# iorx630 register map
Registers are 8-bit, access not given, no defined reset value unless marked. A register's access mark holds for its fields unless they carry their own. Addresses are absolute; registers are grouped by the start of their names; [hi:lo] are bit positions; {n}, {i} and the like mark numbered series; 'fields as' and 'values as' point back to an identical list.

## SFR (part 4 of 4)
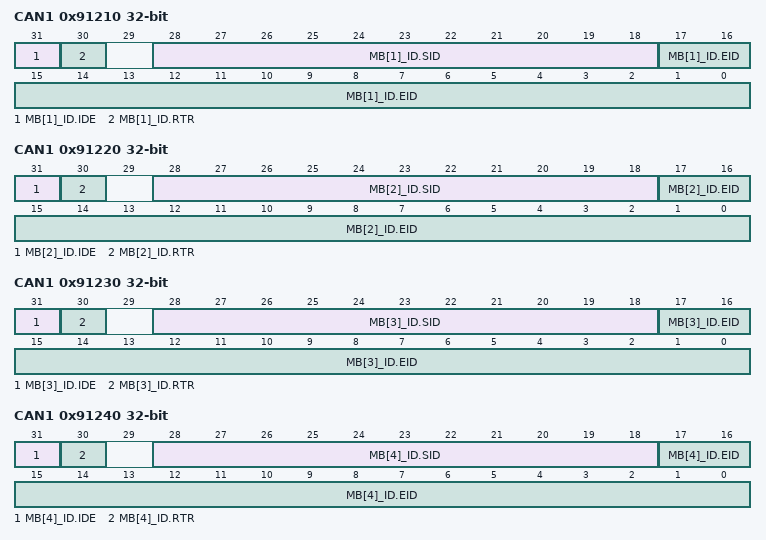
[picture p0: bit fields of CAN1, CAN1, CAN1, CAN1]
0x91210 CAN1 32-bit
  [31] MB[1]_ID.IDE, [30] MB[1]_ID.RTR, [28:18] MB[1]_ID.SID, [17:0] MB[1]_ID.EID
0x91220 CAN1 32-bit
  [31] MB[2]_ID.IDE, [30] MB[2]_ID.RTR, [28:18] MB[2]_ID.SID, [17:0] MB[2]_ID.EID
0x91230 CAN1 32-bit
  [31] MB[3]_ID.IDE, [30] MB[3]_ID.RTR, [28:18] MB[3]_ID.SID, [17:0] MB[3]_ID.EID
0x91240 CAN1 32-bit
  [31] MB[4]_ID.IDE, [30] MB[4]_ID.RTR, [28:18] MB[4]_ID.SID, [17:0] MB[4]_ID.EID
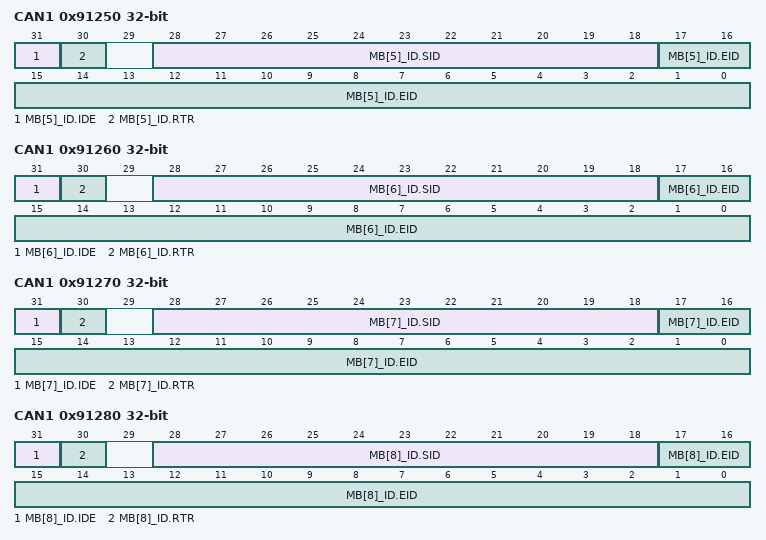
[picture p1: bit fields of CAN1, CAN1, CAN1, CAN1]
0x91250 CAN1 32-bit
  [31] MB[5]_ID.IDE, [30] MB[5]_ID.RTR, [28:18] MB[5]_ID.SID, [17:0] MB[5]_ID.EID
0x91260 CAN1 32-bit
  [31] MB[6]_ID.IDE, [30] MB[6]_ID.RTR, [28:18] MB[6]_ID.SID, [17:0] MB[6]_ID.EID
0x91270 CAN1 32-bit
  [31] MB[7]_ID.IDE, [30] MB[7]_ID.RTR, [28:18] MB[7]_ID.SID, [17:0] MB[7]_ID.EID
0x91280 CAN1 32-bit
  [31] MB[8]_ID.IDE, [30] MB[8]_ID.RTR, [28:18] MB[8]_ID.SID, [17:0] MB[8]_ID.EID
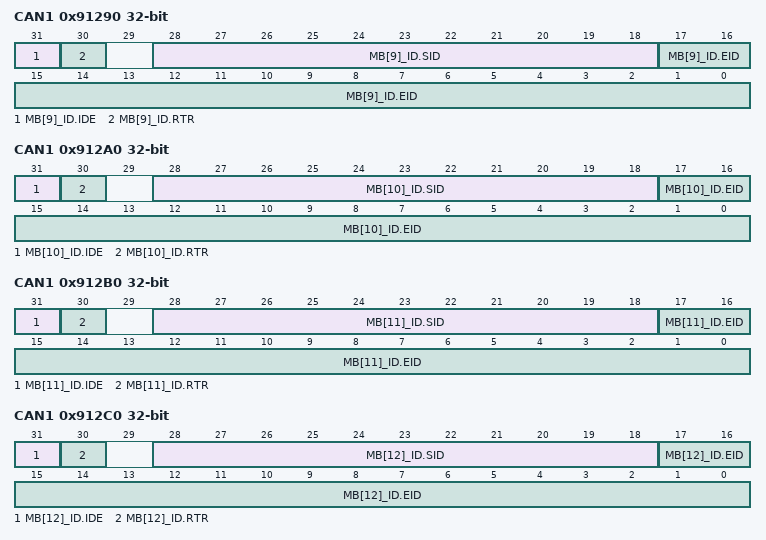
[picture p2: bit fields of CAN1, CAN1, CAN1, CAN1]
0x91290 CAN1 32-bit
  [31] MB[9]_ID.IDE, [30] MB[9]_ID.RTR, [28:18] MB[9]_ID.SID, [17:0] MB[9]_ID.EID
0x912A0 CAN1 32-bit
  [31] MB[10]_ID.IDE, [30] MB[10]_ID.RTR, [28:18] MB[10]_ID.SID, [17:0] MB[10]_ID.EID
0x912B0 CAN1 32-bit
  [31] MB[11]_ID.IDE, [30] MB[11]_ID.RTR, [28:18] MB[11]_ID.SID, [17:0] MB[11]_ID.EID
0x912C0 CAN1 32-bit
  [31] MB[12]_ID.IDE, [30] MB[12]_ID.RTR, [28:18] MB[12]_ID.SID, [17:0] MB[12]_ID.EID
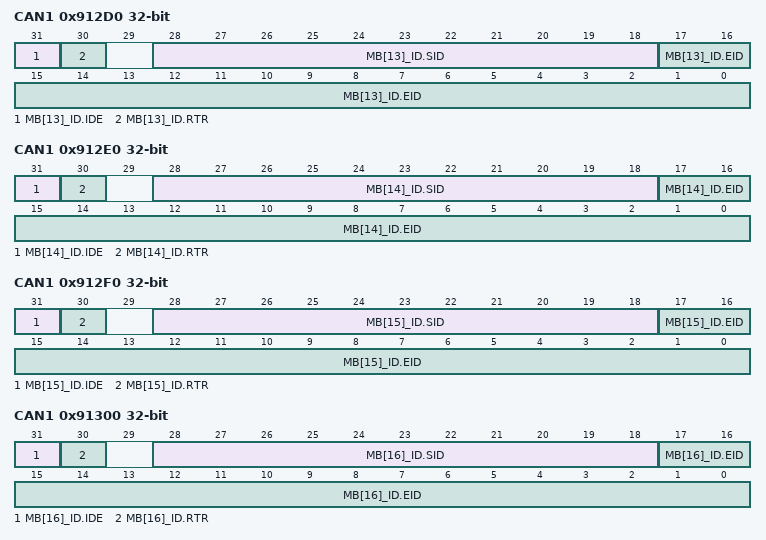
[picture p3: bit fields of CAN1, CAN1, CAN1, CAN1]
0x912D0 CAN1 32-bit
  [31] MB[13]_ID.IDE, [30] MB[13]_ID.RTR, [28:18] MB[13]_ID.SID, [17:0] MB[13]_ID.EID
0x912E0 CAN1 32-bit
  [31] MB[14]_ID.IDE, [30] MB[14]_ID.RTR, [28:18] MB[14]_ID.SID, [17:0] MB[14]_ID.EID
0x912F0 CAN1 32-bit
  [31] MB[15]_ID.IDE, [30] MB[15]_ID.RTR, [28:18] MB[15]_ID.SID, [17:0] MB[15]_ID.EID
0x91300 CAN1 32-bit
  [31] MB[16]_ID.IDE, [30] MB[16]_ID.RTR, [28:18] MB[16]_ID.SID, [17:0] MB[16]_ID.EID
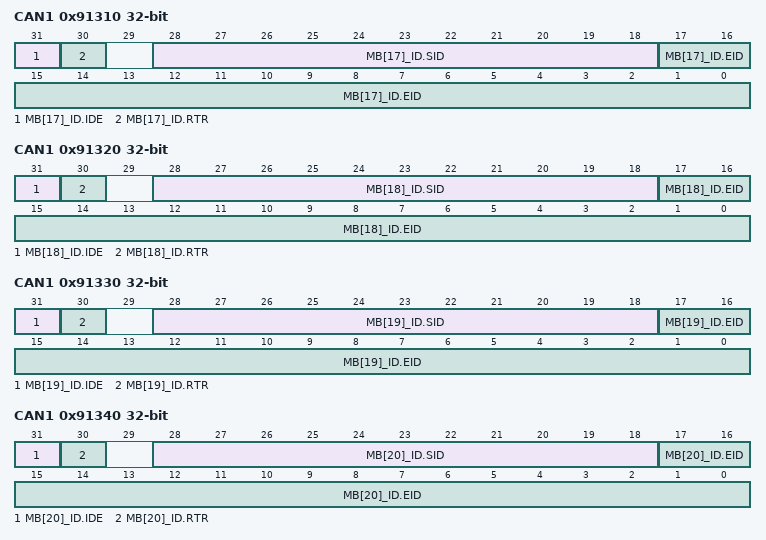
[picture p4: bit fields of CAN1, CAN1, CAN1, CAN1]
0x91310 CAN1 32-bit
  [31] MB[17]_ID.IDE, [30] MB[17]_ID.RTR, [28:18] MB[17]_ID.SID, [17:0] MB[17]_ID.EID
0x91320 CAN1 32-bit
  [31] MB[18]_ID.IDE, [30] MB[18]_ID.RTR, [28:18] MB[18]_ID.SID, [17:0] MB[18]_ID.EID
0x91330 CAN1 32-bit
  [31] MB[19]_ID.IDE, [30] MB[19]_ID.RTR, [28:18] MB[19]_ID.SID, [17:0] MB[19]_ID.EID
0x91340 CAN1 32-bit
  [31] MB[20]_ID.IDE, [30] MB[20]_ID.RTR, [28:18] MB[20]_ID.SID, [17:0] MB[20]_ID.EID
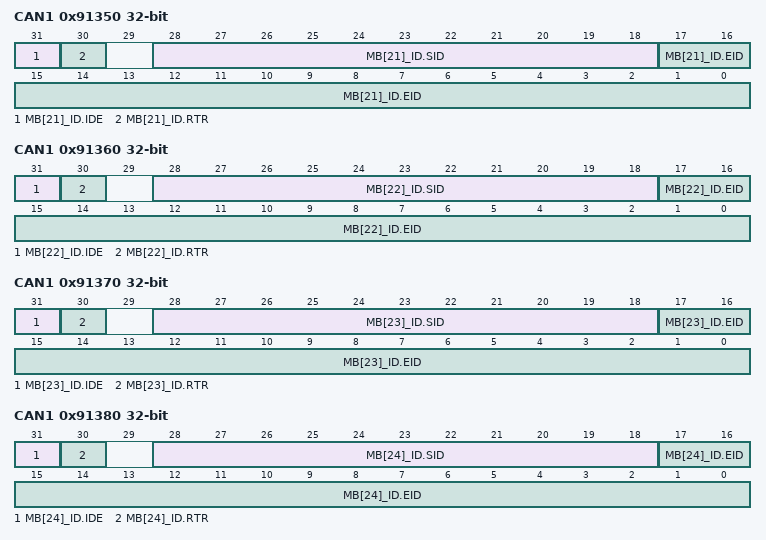
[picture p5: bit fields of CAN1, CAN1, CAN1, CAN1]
0x91350 CAN1 32-bit
  [31] MB[21]_ID.IDE, [30] MB[21]_ID.RTR, [28:18] MB[21]_ID.SID, [17:0] MB[21]_ID.EID
0x91360 CAN1 32-bit
  [31] MB[22]_ID.IDE, [30] MB[22]_ID.RTR, [28:18] MB[22]_ID.SID, [17:0] MB[22]_ID.EID
0x91370 CAN1 32-bit
  [31] MB[23]_ID.IDE, [30] MB[23]_ID.RTR, [28:18] MB[23]_ID.SID, [17:0] MB[23]_ID.EID
0x91380 CAN1 32-bit
  [31] MB[24]_ID.IDE, [30] MB[24]_ID.RTR, [28:18] MB[24]_ID.SID, [17:0] MB[24]_ID.EID
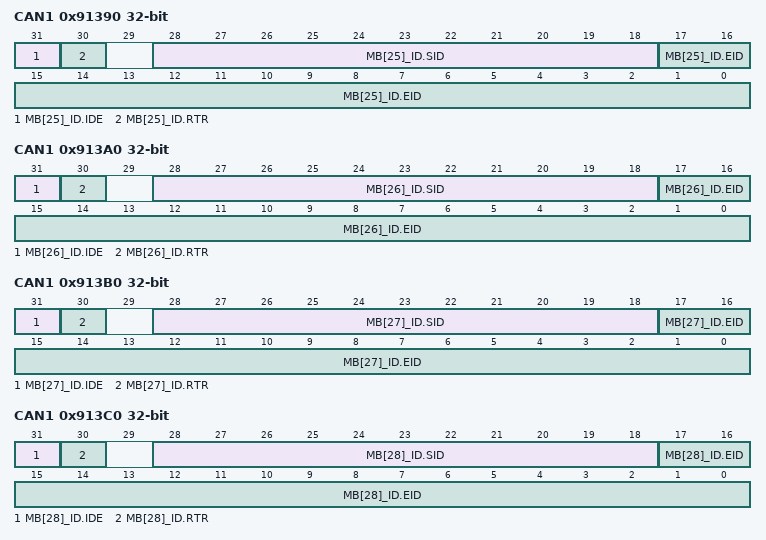
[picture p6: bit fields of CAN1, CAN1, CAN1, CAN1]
0x91390 CAN1 32-bit
  [31] MB[25]_ID.IDE, [30] MB[25]_ID.RTR, [28:18] MB[25]_ID.SID, [17:0] MB[25]_ID.EID
0x913A0 CAN1 32-bit
  [31] MB[26]_ID.IDE, [30] MB[26]_ID.RTR, [28:18] MB[26]_ID.SID, [17:0] MB[26]_ID.EID
0x913B0 CAN1 32-bit
  [31] MB[27]_ID.IDE, [30] MB[27]_ID.RTR, [28:18] MB[27]_ID.SID, [17:0] MB[27]_ID.EID
0x913C0 CAN1 32-bit
  [31] MB[28]_ID.IDE, [30] MB[28]_ID.RTR, [28:18] MB[28]_ID.SID, [17:0] MB[28]_ID.EID
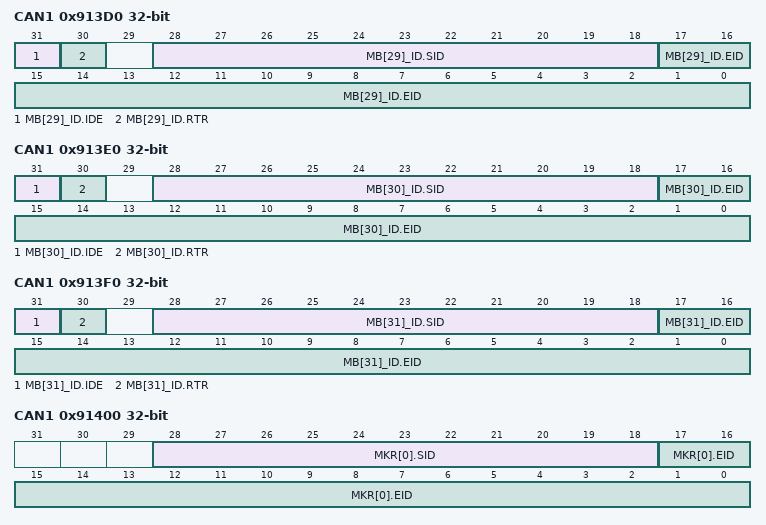
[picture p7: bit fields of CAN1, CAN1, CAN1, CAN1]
0x913D0 CAN1 32-bit
  [31] MB[29]_ID.IDE, [30] MB[29]_ID.RTR, [28:18] MB[29]_ID.SID, [17:0] MB[29]_ID.EID
0x913E0 CAN1 32-bit
  [31] MB[30]_ID.IDE, [30] MB[30]_ID.RTR, [28:18] MB[30]_ID.SID, [17:0] MB[30]_ID.EID
0x913F0 CAN1 32-bit
  [31] MB[31]_ID.IDE, [30] MB[31]_ID.RTR, [28:18] MB[31]_ID.SID, [17:0] MB[31]_ID.EID
0x91400 CAN1 32-bit
  [28:18] MKR[0].SID, [17:0] MKR[0].EID
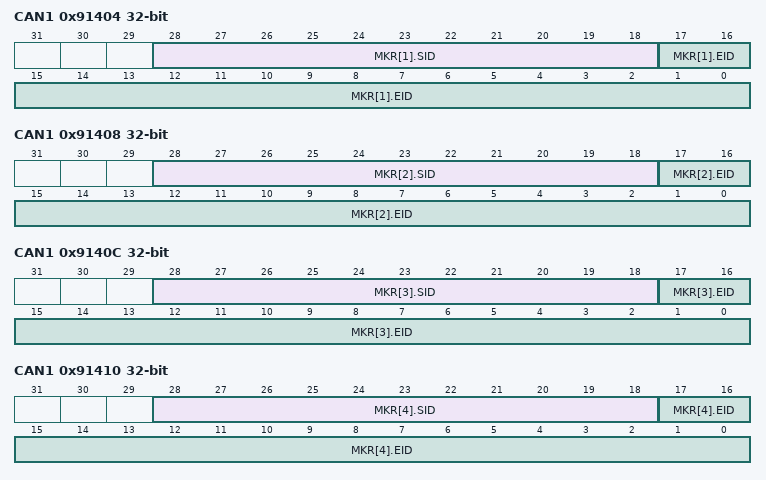
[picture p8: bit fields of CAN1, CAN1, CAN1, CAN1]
0x91404 CAN1 32-bit
  [28:18] MKR[1].SID, [17:0] MKR[1].EID
0x91408 CAN1 32-bit
  [28:18] MKR[2].SID, [17:0] MKR[2].EID
0x9140C CAN1 32-bit
  [28:18] MKR[3].SID, [17:0] MKR[3].EID
0x91410 CAN1 32-bit
  [28:18] MKR[4].SID, [17:0] MKR[4].EID
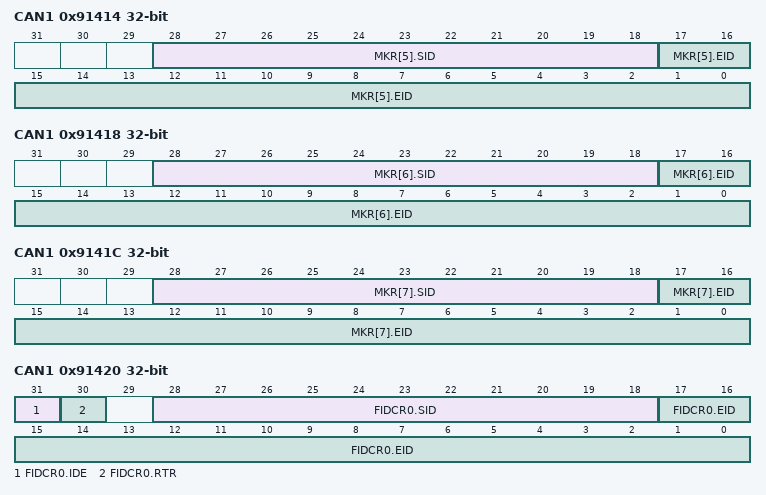
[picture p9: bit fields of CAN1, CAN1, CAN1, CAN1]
0x91414 CAN1 32-bit
  [28:18] MKR[5].SID, [17:0] MKR[5].EID
0x91418 CAN1 32-bit
  [28:18] MKR[6].SID, [17:0] MKR[6].EID
0x9141C CAN1 32-bit
  [28:18] MKR[7].SID, [17:0] MKR[7].EID
0x91420 CAN1 32-bit
  [31] FIDCR0.IDE, [30] FIDCR0.RTR, [28:18] FIDCR0.SID, [17:0] FIDCR0.EID
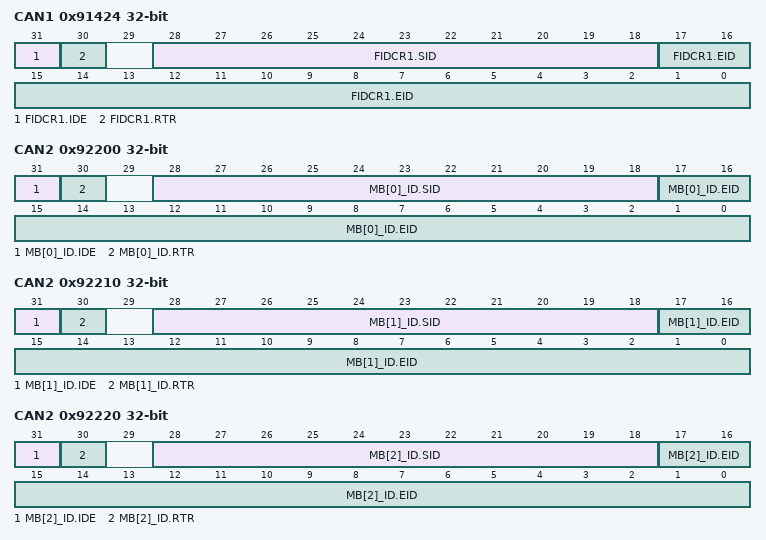
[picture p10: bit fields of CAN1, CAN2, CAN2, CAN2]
0x91424 CAN1 32-bit
  [31] FIDCR1.IDE, [30] FIDCR1.RTR, [28:18] FIDCR1.SID, [17:0] FIDCR1.EID
0x91820 CAN1
  [7] MCTL[0]_TX.TRMREQ, [7] MCTL[0]_RX.TRMREQ, [6] MCTL[0]_TX.RECREQ, [6] MCTL[0]_RX.RECREQ, [4] MCTL[0]_TX.ONESHOT, [4] MCTL[0]_RX.ONESHOT, [2] MCTL[0]_TX.TRMABT, [2] MCTL[0]_RX.MSGLOST, [1] MCTL[0]_TX.TRMACTIVE, [1] MCTL[0]_RX.INVALDATA, [0] MCTL[0]_TX.SENTDATA, [0] MCTL[0]_RX.NEWDATA
0x91821 CAN1
  [7] MCTL[1]_TX.TRMREQ, [7] MCTL[1]_RX.TRMREQ, [6] MCTL[1]_TX.RECREQ, [6] MCTL[1]_RX.RECREQ, [4] MCTL[1]_TX.ONESHOT, [4] MCTL[1]_RX.ONESHOT, [2] MCTL[1]_TX.TRMABT, [2] MCTL[1]_RX.MSGLOST, [1] MCTL[1]_TX.TRMACTIVE, [1] MCTL[1]_RX.INVALDATA, [0] MCTL[1]_TX.SENTDATA, [0] MCTL[1]_RX.NEWDATA
0x91822 CAN1
  [7] MCTL[2]_TX.TRMREQ, [7] MCTL[2]_RX.TRMREQ, [6] MCTL[2]_TX.RECREQ, [6] MCTL[2]_RX.RECREQ, [4] MCTL[2]_TX.ONESHOT, [4] MCTL[2]_RX.ONESHOT, [2] MCTL[2]_TX.TRMABT, [2] MCTL[2]_RX.MSGLOST, [1] MCTL[2]_TX.TRMACTIVE, [1] MCTL[2]_RX.INVALDATA, [0] MCTL[2]_TX.SENTDATA, [0] MCTL[2]_RX.NEWDATA
0x91823 CAN1
  [7] MCTL[3]_TX.TRMREQ, [7] MCTL[3]_RX.TRMREQ, [6] MCTL[3]_TX.RECREQ, [6] MCTL[3]_RX.RECREQ, [4] MCTL[3]_TX.ONESHOT, [4] MCTL[3]_RX.ONESHOT, [2] MCTL[3]_TX.TRMABT, [2] MCTL[3]_RX.MSGLOST, [1] MCTL[3]_TX.TRMACTIVE, [1] MCTL[3]_RX.INVALDATA, [0] MCTL[3]_TX.SENTDATA, [0] MCTL[3]_RX.NEWDATA
0x91824 CAN1
  [7] MCTL[4]_TX.TRMREQ, [7] MCTL[4]_RX.TRMREQ, [6] MCTL[4]_TX.RECREQ, [6] MCTL[4]_RX.RECREQ, [4] MCTL[4]_TX.ONESHOT, [4] MCTL[4]_RX.ONESHOT, [2] MCTL[4]_TX.TRMABT, [2] MCTL[4]_RX.MSGLOST, [1] MCTL[4]_TX.TRMACTIVE, [1] MCTL[4]_RX.INVALDATA, [0] MCTL[4]_TX.SENTDATA, [0] MCTL[4]_RX.NEWDATA
0x91825 CAN1
  [7] MCTL[5]_TX.TRMREQ, [7] MCTL[5]_RX.TRMREQ, [6] MCTL[5]_TX.RECREQ, [6] MCTL[5]_RX.RECREQ, [4] MCTL[5]_TX.ONESHOT, [4] MCTL[5]_RX.ONESHOT, [2] MCTL[5]_TX.TRMABT, [2] MCTL[5]_RX.MSGLOST, [1] MCTL[5]_TX.TRMACTIVE, [1] MCTL[5]_RX.INVALDATA, [0] MCTL[5]_TX.SENTDATA, [0] MCTL[5]_RX.NEWDATA
0x91826 CAN1
  [7] MCTL[6]_TX.TRMREQ, [7] MCTL[6]_RX.TRMREQ, [6] MCTL[6]_TX.RECREQ, [6] MCTL[6]_RX.RECREQ, [4] MCTL[6]_TX.ONESHOT, [4] MCTL[6]_RX.ONESHOT, [2] MCTL[6]_TX.TRMABT, [2] MCTL[6]_RX.MSGLOST, [1] MCTL[6]_TX.TRMACTIVE, [1] MCTL[6]_RX.INVALDATA, [0] MCTL[6]_TX.SENTDATA, [0] MCTL[6]_RX.NEWDATA
0x91827 CAN1
  [7] MCTL[7]_TX.TRMREQ, [7] MCTL[7]_RX.TRMREQ, [6] MCTL[7]_TX.RECREQ, [6] MCTL[7]_RX.RECREQ, [4] MCTL[7]_TX.ONESHOT, [4] MCTL[7]_RX.ONESHOT, [2] MCTL[7]_TX.TRMABT, [2] MCTL[7]_RX.MSGLOST, [1] MCTL[7]_TX.TRMACTIVE, [1] MCTL[7]_RX.INVALDATA, [0] MCTL[7]_TX.SENTDATA, [0] MCTL[7]_RX.NEWDATA
0x91828 CAN1
  [7] MCTL[8]_TX.TRMREQ, [7] MCTL[8]_RX.TRMREQ, [6] MCTL[8]_TX.RECREQ, [6] MCTL[8]_RX.RECREQ, [4] MCTL[8]_TX.ONESHOT, [4] MCTL[8]_RX.ONESHOT, [2] MCTL[8]_TX.TRMABT, [2] MCTL[8]_RX.MSGLOST, [1] MCTL[8]_TX.TRMACTIVE, [1] MCTL[8]_RX.INVALDATA, [0] MCTL[8]_TX.SENTDATA, [0] MCTL[8]_RX.NEWDATA
0x91829 CAN1
  [7] MCTL[9]_TX.TRMREQ, [7] MCTL[9]_RX.TRMREQ, [6] MCTL[9]_TX.RECREQ, [6] MCTL[9]_RX.RECREQ, [4] MCTL[9]_TX.ONESHOT, [4] MCTL[9]_RX.ONESHOT, [2] MCTL[9]_TX.TRMABT, [2] MCTL[9]_RX.MSGLOST, [1] MCTL[9]_TX.TRMACTIVE, [1] MCTL[9]_RX.INVALDATA, [0] MCTL[9]_TX.SENTDATA, [0] MCTL[9]_RX.NEWDATA
0x9182A CAN1
  [7] MCTL[10]_TX.TRMREQ, [7] MCTL[10]_RX.TRMREQ, [6] MCTL[10]_TX.RECREQ, [6] MCTL[10]_RX.RECREQ, [4] MCTL[10]_TX.ONESHOT, [4] MCTL[10]_RX.ONESHOT, [2] MCTL[10]_TX.TRMABT, [2] MCTL[10]_RX.MSGLOST, [1] MCTL[10]_TX.TRMACTIVE, [1] MCTL[10]_RX.INVALDATA, [0] MCTL[10]_TX.SENTDATA, [0] MCTL[10]_RX.NEWDATA
0x9182B CAN1
  [7] MCTL[11]_TX.TRMREQ, [7] MCTL[11]_RX.TRMREQ, [6] MCTL[11]_TX.RECREQ, [6] MCTL[11]_RX.RECREQ, [4] MCTL[11]_TX.ONESHOT, [4] MCTL[11]_RX.ONESHOT, [2] MCTL[11]_TX.TRMABT, [2] MCTL[11]_RX.MSGLOST, [1] MCTL[11]_TX.TRMACTIVE, [1] MCTL[11]_RX.INVALDATA, [0] MCTL[11]_TX.SENTDATA, [0] MCTL[11]_RX.NEWDATA
0x9182C CAN1
  [7] MCTL[12]_TX.TRMREQ, [7] MCTL[12]_RX.TRMREQ, [6] MCTL[12]_TX.RECREQ, [6] MCTL[12]_RX.RECREQ, [4] MCTL[12]_TX.ONESHOT, [4] MCTL[12]_RX.ONESHOT, [2] MCTL[12]_TX.TRMABT, [2] MCTL[12]_RX.MSGLOST, [1] MCTL[12]_TX.TRMACTIVE, [1] MCTL[12]_RX.INVALDATA, [0] MCTL[12]_TX.SENTDATA, [0] MCTL[12]_RX.NEWDATA
0x9182D CAN1
  [7] MCTL[13]_TX.TRMREQ, [7] MCTL[13]_RX.TRMREQ, [6] MCTL[13]_TX.RECREQ, [6] MCTL[13]_RX.RECREQ, [4] MCTL[13]_TX.ONESHOT, [4] MCTL[13]_RX.ONESHOT, [2] MCTL[13]_TX.TRMABT, [2] MCTL[13]_RX.MSGLOST, [1] MCTL[13]_TX.TRMACTIVE, [1] MCTL[13]_RX.INVALDATA, [0] MCTL[13]_TX.SENTDATA, [0] MCTL[13]_RX.NEWDATA
0x9182E CAN1
  [7] MCTL[14]_TX.TRMREQ, [7] MCTL[14]_RX.TRMREQ, [6] MCTL[14]_TX.RECREQ, [6] MCTL[14]_RX.RECREQ, [4] MCTL[14]_TX.ONESHOT, [4] MCTL[14]_RX.ONESHOT, [2] MCTL[14]_TX.TRMABT, [2] MCTL[14]_RX.MSGLOST, [1] MCTL[14]_TX.TRMACTIVE, [1] MCTL[14]_RX.INVALDATA, [0] MCTL[14]_TX.SENTDATA, [0] MCTL[14]_RX.NEWDATA
0x9182F CAN1
  [7] MCTL[15]_TX.TRMREQ, [7] MCTL[15]_RX.TRMREQ, [6] MCTL[15]_TX.RECREQ, [6] MCTL[15]_RX.RECREQ, [4] MCTL[15]_TX.ONESHOT, [4] MCTL[15]_RX.ONESHOT, [2] MCTL[15]_TX.TRMABT, [2] MCTL[15]_RX.MSGLOST, [1] MCTL[15]_TX.TRMACTIVE, [1] MCTL[15]_RX.INVALDATA, [0] MCTL[15]_TX.SENTDATA, [0] MCTL[15]_RX.NEWDATA
0x91830 CAN1
  [7] MCTL[16]_TX.TRMREQ, [7] MCTL[16]_RX.TRMREQ, [6] MCTL[16]_TX.RECREQ, [6] MCTL[16]_RX.RECREQ, [4] MCTL[16]_TX.ONESHOT, [4] MCTL[16]_RX.ONESHOT, [2] MCTL[16]_TX.TRMABT, [2] MCTL[16]_RX.MSGLOST, [1] MCTL[16]_TX.TRMACTIVE, [1] MCTL[16]_RX.INVALDATA, [0] MCTL[16]_TX.SENTDATA, [0] MCTL[16]_RX.NEWDATA
0x91831 CAN1
  [7] MCTL[17]_TX.TRMREQ, [7] MCTL[17]_RX.TRMREQ, [6] MCTL[17]_TX.RECREQ, [6] MCTL[17]_RX.RECREQ, [4] MCTL[17]_TX.ONESHOT, [4] MCTL[17]_RX.ONESHOT, [2] MCTL[17]_TX.TRMABT, [2] MCTL[17]_RX.MSGLOST, [1] MCTL[17]_TX.TRMACTIVE, [1] MCTL[17]_RX.INVALDATA, [0] MCTL[17]_TX.SENTDATA, [0] MCTL[17]_RX.NEWDATA
0x91832 CAN1
  [7] MCTL[18]_TX.TRMREQ, [7] MCTL[18]_RX.TRMREQ, [6] MCTL[18]_TX.RECREQ, [6] MCTL[18]_RX.RECREQ, [4] MCTL[18]_TX.ONESHOT, [4] MCTL[18]_RX.ONESHOT, [2] MCTL[18]_TX.TRMABT, [2] MCTL[18]_RX.MSGLOST, [1] MCTL[18]_TX.TRMACTIVE, [1] MCTL[18]_RX.INVALDATA, [0] MCTL[18]_TX.SENTDATA, [0] MCTL[18]_RX.NEWDATA
0x91833 CAN1
  [7] MCTL[19]_TX.TRMREQ, [7] MCTL[19]_RX.TRMREQ, [6] MCTL[19]_TX.RECREQ, [6] MCTL[19]_RX.RECREQ, [4] MCTL[19]_TX.ONESHOT, [4] MCTL[19]_RX.ONESHOT, [2] MCTL[19]_TX.TRMABT, [2] MCTL[19]_RX.MSGLOST, [1] MCTL[19]_TX.TRMACTIVE, [1] MCTL[19]_RX.INVALDATA, [0] MCTL[19]_TX.SENTDATA, [0] MCTL[19]_RX.NEWDATA
0x91834 CAN1
  [7] MCTL[20]_TX.TRMREQ, [7] MCTL[20]_RX.TRMREQ, [6] MCTL[20]_TX.RECREQ, [6] MCTL[20]_RX.RECREQ, [4] MCTL[20]_TX.ONESHOT, [4] MCTL[20]_RX.ONESHOT, [2] MCTL[20]_TX.TRMABT, [2] MCTL[20]_RX.MSGLOST, [1] MCTL[20]_TX.TRMACTIVE, [1] MCTL[20]_RX.INVALDATA, [0] MCTL[20]_TX.SENTDATA, [0] MCTL[20]_RX.NEWDATA
0x91835 CAN1
  [7] MCTL[21]_TX.TRMREQ, [7] MCTL[21]_RX.TRMREQ, [6] MCTL[21]_TX.RECREQ, [6] MCTL[21]_RX.RECREQ, [4] MCTL[21]_TX.ONESHOT, [4] MCTL[21]_RX.ONESHOT, [2] MCTL[21]_TX.TRMABT, [2] MCTL[21]_RX.MSGLOST, [1] MCTL[21]_TX.TRMACTIVE, [1] MCTL[21]_RX.INVALDATA, [0] MCTL[21]_TX.SENTDATA, [0] MCTL[21]_RX.NEWDATA
0x91836 CAN1
  [7] MCTL[22]_TX.TRMREQ, [7] MCTL[22]_RX.TRMREQ, [6] MCTL[22]_TX.RECREQ, [6] MCTL[22]_RX.RECREQ, [4] MCTL[22]_TX.ONESHOT, [4] MCTL[22]_RX.ONESHOT, [2] MCTL[22]_TX.TRMABT, [2] MCTL[22]_RX.MSGLOST, [1] MCTL[22]_TX.TRMACTIVE, [1] MCTL[22]_RX.INVALDATA, [0] MCTL[22]_TX.SENTDATA, [0] MCTL[22]_RX.NEWDATA
0x91837 CAN1
  [7] MCTL[23]_TX.TRMREQ, [7] MCTL[23]_RX.TRMREQ, [6] MCTL[23]_TX.RECREQ, [6] MCTL[23]_RX.RECREQ, [4] MCTL[23]_TX.ONESHOT, [4] MCTL[23]_RX.ONESHOT, [2] MCTL[23]_TX.TRMABT, [2] MCTL[23]_RX.MSGLOST, [1] MCTL[23]_TX.TRMACTIVE, [1] MCTL[23]_RX.INVALDATA, [0] MCTL[23]_TX.SENTDATA, [0] MCTL[23]_RX.NEWDATA
0x91838 CAN1
  [7] MCTL[24]_TX.TRMREQ, [7] MCTL[24]_RX.TRMREQ, [6] MCTL[24]_TX.RECREQ, [6] MCTL[24]_RX.RECREQ, [4] MCTL[24]_TX.ONESHOT, [4] MCTL[24]_RX.ONESHOT, [2] MCTL[24]_TX.TRMABT, [2] MCTL[24]_RX.MSGLOST, [1] MCTL[24]_TX.TRMACTIVE, [1] MCTL[24]_RX.INVALDATA, [0] MCTL[24]_TX.SENTDATA, [0] MCTL[24]_RX.NEWDATA
0x91839 CAN1
  [7] MCTL[25]_TX.TRMREQ, [7] MCTL[25]_RX.TRMREQ, [6] MCTL[25]_TX.RECREQ, [6] MCTL[25]_RX.RECREQ, [4] MCTL[25]_TX.ONESHOT, [4] MCTL[25]_RX.ONESHOT, [2] MCTL[25]_TX.TRMABT, [2] MCTL[25]_RX.MSGLOST, [1] MCTL[25]_TX.TRMACTIVE, [1] MCTL[25]_RX.INVALDATA, [0] MCTL[25]_TX.SENTDATA, [0] MCTL[25]_RX.NEWDATA
0x9183A CAN1
  [7] MCTL[26]_TX.TRMREQ, [7] MCTL[26]_RX.TRMREQ, [6] MCTL[26]_TX.RECREQ, [6] MCTL[26]_RX.RECREQ, [4] MCTL[26]_TX.ONESHOT, [4] MCTL[26]_RX.ONESHOT, [2] MCTL[26]_TX.TRMABT, [2] MCTL[26]_RX.MSGLOST, [1] MCTL[26]_TX.TRMACTIVE, [1] MCTL[26]_RX.INVALDATA, [0] MCTL[26]_TX.SENTDATA, [0] MCTL[26]_RX.NEWDATA
0x9183B CAN1
  [7] MCTL[27]_TX.TRMREQ, [7] MCTL[27]_RX.TRMREQ, [6] MCTL[27]_TX.RECREQ, [6] MCTL[27]_RX.RECREQ, [4] MCTL[27]_TX.ONESHOT, [4] MCTL[27]_RX.ONESHOT, [2] MCTL[27]_TX.TRMABT, [2] MCTL[27]_RX.MSGLOST, [1] MCTL[27]_TX.TRMACTIVE, [1] MCTL[27]_RX.INVALDATA, [0] MCTL[27]_TX.SENTDATA, [0] MCTL[27]_RX.NEWDATA
0x9183C CAN1
  [7] MCTL[28]_TX.TRMREQ, [7] MCTL[28]_RX.TRMREQ, [6] MCTL[28]_TX.RECREQ, [6] MCTL[28]_RX.RECREQ, [4] MCTL[28]_TX.ONESHOT, [4] MCTL[28]_RX.ONESHOT, [2] MCTL[28]_TX.TRMABT, [2] MCTL[28]_RX.MSGLOST, [1] MCTL[28]_TX.TRMACTIVE, [1] MCTL[28]_RX.INVALDATA, [0] MCTL[28]_TX.SENTDATA, [0] MCTL[28]_RX.NEWDATA
0x9183D CAN1
  [7] MCTL[29]_TX.TRMREQ, [7] MCTL[29]_RX.TRMREQ, [6] MCTL[29]_TX.RECREQ, [6] MCTL[29]_RX.RECREQ, [4] MCTL[29]_TX.ONESHOT, [4] MCTL[29]_RX.ONESHOT, [2] MCTL[29]_TX.TRMABT, [2] MCTL[29]_RX.MSGLOST, [1] MCTL[29]_TX.TRMACTIVE, [1] MCTL[29]_RX.INVALDATA, [0] MCTL[29]_TX.SENTDATA, [0] MCTL[29]_RX.NEWDATA
0x9183E CAN1
  [7] MCTL[30]_TX.TRMREQ, [7] MCTL[30]_RX.TRMREQ, [6] MCTL[30]_TX.RECREQ, [6] MCTL[30]_RX.RECREQ, [4] MCTL[30]_TX.ONESHOT, [4] MCTL[30]_RX.ONESHOT, [2] MCTL[30]_TX.TRMABT, [2] MCTL[30]_RX.MSGLOST, [1] MCTL[30]_TX.TRMACTIVE, [1] MCTL[30]_RX.INVALDATA, [0] MCTL[30]_TX.SENTDATA, [0] MCTL[30]_RX.NEWDATA
0x9183F CAN1
  [7] MCTL[31]_TX.TRMREQ, [7] MCTL[31]_RX.TRMREQ, [6] MCTL[31]_TX.RECREQ, [6] MCTL[31]_RX.RECREQ, [4] MCTL[31]_TX.ONESHOT, [4] MCTL[31]_RX.ONESHOT, [2] MCTL[31]_TX.TRMABT, [2] MCTL[31]_RX.MSGLOST, [1] MCTL[31]_TX.TRMACTIVE, [1] MCTL[31]_RX.INVALDATA, [0] MCTL[31]_TX.SENTDATA, [0] MCTL[31]_RX.NEWDATA
0x92200 CAN2 32-bit
  [31] MB[0]_ID.IDE, [30] MB[0]_ID.RTR, [28:18] MB[0]_ID.SID, [17:0] MB[0]_ID.EID
0x92210 CAN2 32-bit
  fields as CAN1
0x92220 CAN2 32-bit
  [31] MB[2]_ID.IDE, [30] MB[2]_ID.RTR, [28:18] MB[2]_ID.SID, [17:0] MB[2]_ID.EID
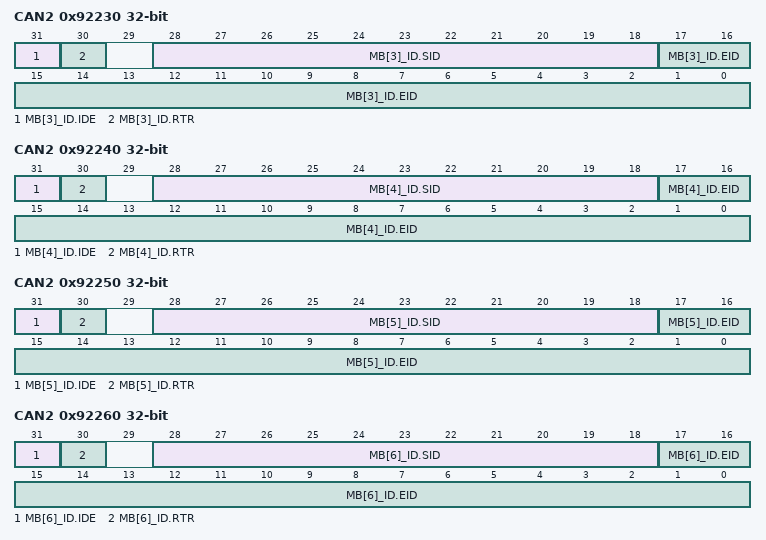
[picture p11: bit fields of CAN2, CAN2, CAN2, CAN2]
0x92230 CAN2 32-bit
  [31] MB[3]_ID.IDE, [30] MB[3]_ID.RTR, [28:18] MB[3]_ID.SID, [17:0] MB[3]_ID.EID
0x92240 CAN2 32-bit
  [31] MB[4]_ID.IDE, [30] MB[4]_ID.RTR, [28:18] MB[4]_ID.SID, [17:0] MB[4]_ID.EID
0x92250 CAN2 32-bit
  [31] MB[5]_ID.IDE, [30] MB[5]_ID.RTR, [28:18] MB[5]_ID.SID, [17:0] MB[5]_ID.EID
0x92260 CAN2 32-bit
  [31] MB[6]_ID.IDE, [30] MB[6]_ID.RTR, [28:18] MB[6]_ID.SID, [17:0] MB[6]_ID.EID
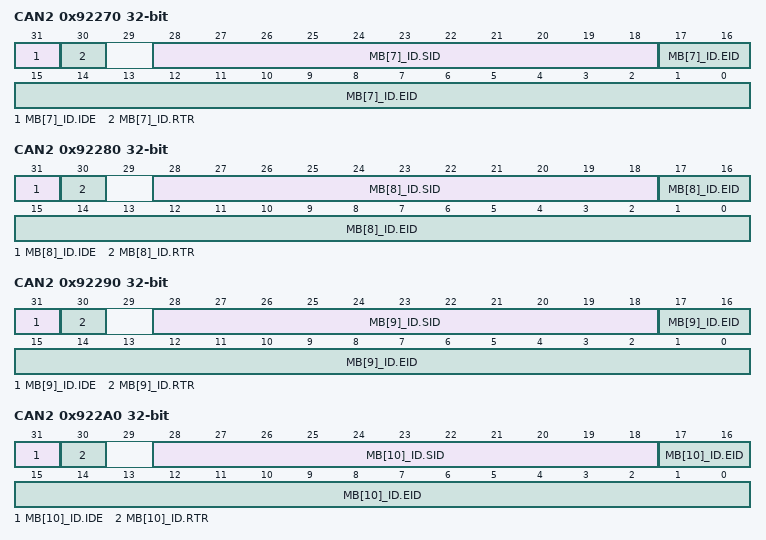
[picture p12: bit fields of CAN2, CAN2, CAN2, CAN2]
0x92270 CAN2 32-bit
  [31] MB[7]_ID.IDE, [30] MB[7]_ID.RTR, [28:18] MB[7]_ID.SID, [17:0] MB[7]_ID.EID
0x92280 CAN2 32-bit
  [31] MB[8]_ID.IDE, [30] MB[8]_ID.RTR, [28:18] MB[8]_ID.SID, [17:0] MB[8]_ID.EID
0x92290 CAN2 32-bit
  [31] MB[9]_ID.IDE, [30] MB[9]_ID.RTR, [28:18] MB[9]_ID.SID, [17:0] MB[9]_ID.EID
0x922A0 CAN2 32-bit
  [31] MB[10]_ID.IDE, [30] MB[10]_ID.RTR, [28:18] MB[10]_ID.SID, [17:0] MB[10]_ID.EID
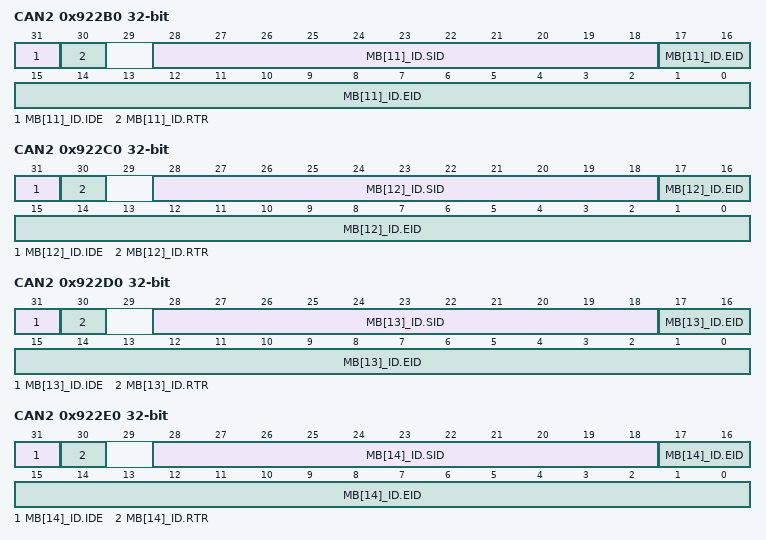
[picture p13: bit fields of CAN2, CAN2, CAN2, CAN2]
0x922B0 CAN2 32-bit
  [31] MB[11]_ID.IDE, [30] MB[11]_ID.RTR, [28:18] MB[11]_ID.SID, [17:0] MB[11]_ID.EID
0x922C0 CAN2 32-bit
  [31] MB[12]_ID.IDE, [30] MB[12]_ID.RTR, [28:18] MB[12]_ID.SID, [17:0] MB[12]_ID.EID
0x922D0 CAN2 32-bit
  [31] MB[13]_ID.IDE, [30] MB[13]_ID.RTR, [28:18] MB[13]_ID.SID, [17:0] MB[13]_ID.EID
0x922E0 CAN2 32-bit
  [31] MB[14]_ID.IDE, [30] MB[14]_ID.RTR, [28:18] MB[14]_ID.SID, [17:0] MB[14]_ID.EID
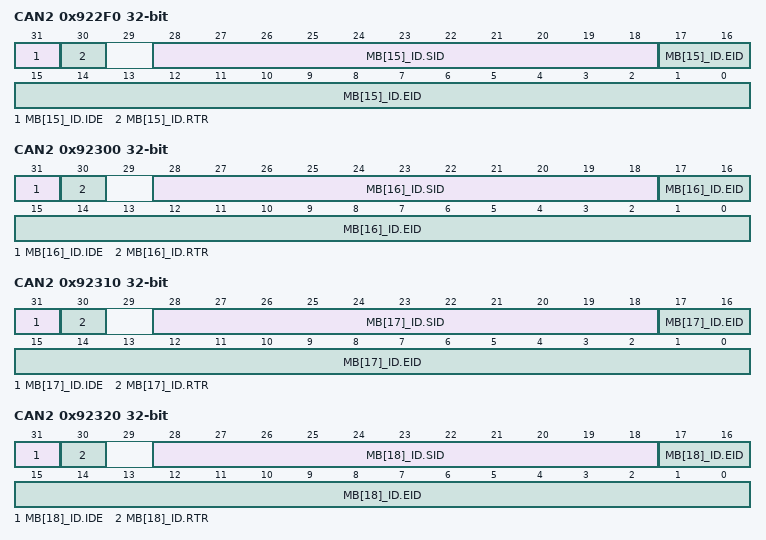
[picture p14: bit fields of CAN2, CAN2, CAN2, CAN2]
0x922F0 CAN2 32-bit
  [31] MB[15]_ID.IDE, [30] MB[15]_ID.RTR, [28:18] MB[15]_ID.SID, [17:0] MB[15]_ID.EID
0x92300 CAN2 32-bit
  [31] MB[16]_ID.IDE, [30] MB[16]_ID.RTR, [28:18] MB[16]_ID.SID, [17:0] MB[16]_ID.EID
0x92310 CAN2 32-bit
  [31] MB[17]_ID.IDE, [30] MB[17]_ID.RTR, [28:18] MB[17]_ID.SID, [17:0] MB[17]_ID.EID
0x92320 CAN2 32-bit
  [31] MB[18]_ID.IDE, [30] MB[18]_ID.RTR, [28:18] MB[18]_ID.SID, [17:0] MB[18]_ID.EID
0x92330 CAN2 32-bit
  [31] MB[19]_ID.IDE, [30] MB[19]_ID.RTR, [28:18] MB[19]_ID.SID, [17:0] MB[19]_ID.EID
0x92340 CAN2 32-bit
  [31] MB[20]_ID.IDE, [30] MB[20]_ID.RTR, [28:18] MB[20]_ID.SID, [17:0] MB[20]_ID.EID
0x92350 CAN2 32-bit
  [31] MB[21]_ID.IDE, [30] MB[21]_ID.RTR, [28:18] MB[21]_ID.SID, [17:0] MB[21]_ID.EID
0x92360 CAN2 32-bit
  [31] MB[22]_ID.IDE, [30] MB[22]_ID.RTR, [28:18] MB[22]_ID.SID, [17:0] MB[22]_ID.EID
0x92370 CAN2 32-bit
  [31] MB[23]_ID.IDE, [30] MB[23]_ID.RTR, [28:18] MB[23]_ID.SID, [17:0] MB[23]_ID.EID
0x92380 CAN2 32-bit
  [31] MB[24]_ID.IDE, [30] MB[24]_ID.RTR, [28:18] MB[24]_ID.SID, [17:0] MB[24]_ID.EID
0x92390 CAN2 32-bit
  [31] MB[25]_ID.IDE, [30] MB[25]_ID.RTR, [28:18] MB[25]_ID.SID, [17:0] MB[25]_ID.EID
0x923A0 CAN2 32-bit
  [31] MB[26]_ID.IDE, [30] MB[26]_ID.RTR, [28:18] MB[26]_ID.SID, [17:0] MB[26]_ID.EID
0x923B0 CAN2 32-bit
  [31] MB[27]_ID.IDE, [30] MB[27]_ID.RTR, [28:18] MB[27]_ID.SID, [17:0] MB[27]_ID.EID
0x923C0 CAN2 32-bit
  [31] MB[28]_ID.IDE, [30] MB[28]_ID.RTR, [28:18] MB[28]_ID.SID, [17:0] MB[28]_ID.EID
0x923D0 CAN2 32-bit
  [31] MB[29]_ID.IDE, [30] MB[29]_ID.RTR, [28:18] MB[29]_ID.SID, [17:0] MB[29]_ID.EID
0x923E0 CAN2 32-bit
  [31] MB[30]_ID.IDE, [30] MB[30]_ID.RTR, [28:18] MB[30]_ID.SID, [17:0] MB[30]_ID.EID
0x923F0 CAN2 32-bit
  [31] MB[31]_ID.IDE, [30] MB[31]_ID.RTR, [28:18] MB[31]_ID.SID, [17:0] MB[31]_ID.EID
0x92400 CAN2 32-bit
  [28:18] MKR[0].SID, [17:0] MKR[0].EID
0x92404 CAN2 32-bit
  [28:18] MKR[1].SID, [17:0] MKR[1].EID
0x92408 CAN2 32-bit
  [28:18] MKR[2].SID, [17:0] MKR[2].EID
0x9240C CAN2 32-bit
  [28:18] MKR[3].SID, [17:0] MKR[3].EID
0x92410 CAN2 32-bit
  [28:18] MKR[4].SID, [17:0] MKR[4].EID
0x92414 CAN2 32-bit
  [28:18] MKR[5].SID, [17:0] MKR[5].EID
0x92418 CAN2 32-bit
  [28:18] MKR[6].SID, [17:0] MKR[6].EID
0x9241C CAN2 32-bit
  [28:18] MKR[7].SID, [17:0] MKR[7].EID
0x92420 CAN2 32-bit
  [31] FIDCR0.IDE, [30] FIDCR0.RTR, [28:18] FIDCR0.SID, [17:0] FIDCR0.EID
0x92424 CAN2 32-bit
  [31] FIDCR1.IDE, [30] FIDCR1.RTR, [28:18] FIDCR1.SID, [17:0] FIDCR1.EID
0x92820 CAN2
  [7] MCTL[0]_TX.TRMREQ, [7] MCTL[0]_RX.TRMREQ, [6] MCTL[0]_TX.RECREQ, [6] MCTL[0]_RX.RECREQ, [4] MCTL[0]_TX.ONESHOT, [4] MCTL[0]_RX.ONESHOT, [2] MCTL[0]_TX.TRMABT, [2] MCTL[0]_RX.MSGLOST, [1] MCTL[0]_TX.TRMACTIVE, [1] MCTL[0]_RX.INVALDATA, [0] MCTL[0]_TX.SENTDATA, [0] MCTL[0]_RX.NEWDATA
0x92821 CAN2
  [7] MCTL[1]_TX.TRMREQ, [7] MCTL[1]_RX.TRMREQ, [6] MCTL[1]_TX.RECREQ, [6] MCTL[1]_RX.RECREQ, [4] MCTL[1]_TX.ONESHOT, [4] MCTL[1]_RX.ONESHOT, [2] MCTL[1]_TX.TRMABT, [2] MCTL[1]_RX.MSGLOST, [1] MCTL[1]_TX.TRMACTIVE, [1] MCTL[1]_RX.INVALDATA, [0] MCTL[1]_TX.SENTDATA, [0] MCTL[1]_RX.NEWDATA
0x92822 CAN2
  [7] MCTL[2]_TX.TRMREQ, [7] MCTL[2]_RX.TRMREQ, [6] MCTL[2]_TX.RECREQ, [6] MCTL[2]_RX.RECREQ, [4] MCTL[2]_TX.ONESHOT, [4] MCTL[2]_RX.ONESHOT, [2] MCTL[2]_TX.TRMABT, [2] MCTL[2]_RX.MSGLOST, [1] MCTL[2]_TX.TRMACTIVE, [1] MCTL[2]_RX.INVALDATA, [0] MCTL[2]_TX.SENTDATA, [0] MCTL[2]_RX.NEWDATA
0x92823 CAN2
  [7] MCTL[3]_TX.TRMREQ, [7] MCTL[3]_RX.TRMREQ, [6] MCTL[3]_TX.RECREQ, [6] MCTL[3]_RX.RECREQ, [4] MCTL[3]_TX.ONESHOT, [4] MCTL[3]_RX.ONESHOT, [2] MCTL[3]_TX.TRMABT, [2] MCTL[3]_RX.MSGLOST, [1] MCTL[3]_TX.TRMACTIVE, [1] MCTL[3]_RX.INVALDATA, [0] MCTL[3]_TX.SENTDATA, [0] MCTL[3]_RX.NEWDATA
0x92824 CAN2
  [7] MCTL[4]_TX.TRMREQ, [7] MCTL[4]_RX.TRMREQ, [6] MCTL[4]_TX.RECREQ, [6] MCTL[4]_RX.RECREQ, [4] MCTL[4]_TX.ONESHOT, [4] MCTL[4]_RX.ONESHOT, [2] MCTL[4]_TX.TRMABT, [2] MCTL[4]_RX.MSGLOST, [1] MCTL[4]_TX.TRMACTIVE, [1] MCTL[4]_RX.INVALDATA, [0] MCTL[4]_TX.SENTDATA, [0] MCTL[4]_RX.NEWDATA
0x92825 CAN2
  [7] MCTL[5]_TX.TRMREQ, [7] MCTL[5]_RX.TRMREQ, [6] MCTL[5]_TX.RECREQ, [6] MCTL[5]_RX.RECREQ, [4] MCTL[5]_TX.ONESHOT, [4] MCTL[5]_RX.ONESHOT, [2] MCTL[5]_TX.TRMABT, [2] MCTL[5]_RX.MSGLOST, [1] MCTL[5]_TX.TRMACTIVE, [1] MCTL[5]_RX.INVALDATA, [0] MCTL[5]_TX.SENTDATA, [0] MCTL[5]_RX.NEWDATA
0x92826 CAN2
  [7] MCTL[6]_TX.TRMREQ, [7] MCTL[6]_RX.TRMREQ, [6] MCTL[6]_TX.RECREQ, [6] MCTL[6]_RX.RECREQ, [4] MCTL[6]_TX.ONESHOT, [4] MCTL[6]_RX.ONESHOT, [2] MCTL[6]_TX.TRMABT, [2] MCTL[6]_RX.MSGLOST, [1] MCTL[6]_TX.TRMACTIVE, [1] MCTL[6]_RX.INVALDATA, [0] MCTL[6]_TX.SENTDATA, [0] MCTL[6]_RX.NEWDATA
0x92827 CAN2
  [7] MCTL[7]_TX.TRMREQ, [7] MCTL[7]_RX.TRMREQ, [6] MCTL[7]_TX.RECREQ, [6] MCTL[7]_RX.RECREQ, [4] MCTL[7]_TX.ONESHOT, [4] MCTL[7]_RX.ONESHOT, [2] MCTL[7]_TX.TRMABT, [2] MCTL[7]_RX.MSGLOST, [1] MCTL[7]_TX.TRMACTIVE, [1] MCTL[7]_RX.INVALDATA, [0] MCTL[7]_TX.SENTDATA, [0] MCTL[7]_RX.NEWDATA
0x92828 CAN2
  [7] MCTL[8]_TX.TRMREQ, [7] MCTL[8]_RX.TRMREQ, [6] MCTL[8]_TX.RECREQ, [6] MCTL[8]_RX.RECREQ, [4] MCTL[8]_TX.ONESHOT, [4] MCTL[8]_RX.ONESHOT, [2] MCTL[8]_TX.TRMABT, [2] MCTL[8]_RX.MSGLOST, [1] MCTL[8]_TX.TRMACTIVE, [1] MCTL[8]_RX.INVALDATA, [0] MCTL[8]_TX.SENTDATA, [0] MCTL[8]_RX.NEWDATA
0x92829 CAN2
  [7] MCTL[9]_TX.TRMREQ, [7] MCTL[9]_RX.TRMREQ, [6] MCTL[9]_TX.RECREQ, [6] MCTL[9]_RX.RECREQ, [4] MCTL[9]_TX.ONESHOT, [4] MCTL[9]_RX.ONESHOT, [2] MCTL[9]_TX.TRMABT, [2] MCTL[9]_RX.MSGLOST, [1] MCTL[9]_TX.TRMACTIVE, [1] MCTL[9]_RX.INVALDATA, [0] MCTL[9]_TX.SENTDATA, [0] MCTL[9]_RX.NEWDATA
0x9282A CAN2
  [7] MCTL[10]_TX.TRMREQ, [7] MCTL[10]_RX.TRMREQ, [6] MCTL[10]_TX.RECREQ, [6] MCTL[10]_RX.RECREQ, [4] MCTL[10]_TX.ONESHOT, [4] MCTL[10]_RX.ONESHOT, [2] MCTL[10]_TX.TRMABT, [2] MCTL[10]_RX.MSGLOST, [1] MCTL[10]_TX.TRMACTIVE, [1] MCTL[10]_RX.INVALDATA, [0] MCTL[10]_TX.SENTDATA, [0] MCTL[10]_RX.NEWDATA
0x9282B CAN2
  [7] MCTL[11]_TX.TRMREQ, [7] MCTL[11]_RX.TRMREQ, [6] MCTL[11]_TX.RECREQ, [6] MCTL[11]_RX.RECREQ, [4] MCTL[11]_TX.ONESHOT, [4] MCTL[11]_RX.ONESHOT, [2] MCTL[11]_TX.TRMABT, [2] MCTL[11]_RX.MSGLOST, [1] MCTL[11]_TX.TRMACTIVE, [1] MCTL[11]_RX.INVALDATA, [0] MCTL[11]_TX.SENTDATA, [0] MCTL[11]_RX.NEWDATA
0x9282C CAN2
  [7] MCTL[12]_TX.TRMREQ, [7] MCTL[12]_RX.TRMREQ, [6] MCTL[12]_TX.RECREQ, [6] MCTL[12]_RX.RECREQ, [4] MCTL[12]_TX.ONESHOT, [4] MCTL[12]_RX.ONESHOT, [2] MCTL[12]_TX.TRMABT, [2] MCTL[12]_RX.MSGLOST, [1] MCTL[12]_TX.TRMACTIVE, [1] MCTL[12]_RX.INVALDATA, [0] MCTL[12]_TX.SENTDATA, [0] MCTL[12]_RX.NEWDATA
0x9282D CAN2
  [7] MCTL[13]_TX.TRMREQ, [7] MCTL[13]_RX.TRMREQ, [6] MCTL[13]_TX.RECREQ, [6] MCTL[13]_RX.RECREQ, [4] MCTL[13]_TX.ONESHOT, [4] MCTL[13]_RX.ONESHOT, [2] MCTL[13]_TX.TRMABT, [2] MCTL[13]_RX.MSGLOST, [1] MCTL[13]_TX.TRMACTIVE, [1] MCTL[13]_RX.INVALDATA, [0] MCTL[13]_TX.SENTDATA, [0] MCTL[13]_RX.NEWDATA
0x9282E CAN2
  [7] MCTL[14]_TX.TRMREQ, [7] MCTL[14]_RX.TRMREQ, [6] MCTL[14]_TX.RECREQ, [6] MCTL[14]_RX.RECREQ, [4] MCTL[14]_TX.ONESHOT, [4] MCTL[14]_RX.ONESHOT, [2] MCTL[14]_TX.TRMABT, [2] MCTL[14]_RX.MSGLOST, [1] MCTL[14]_TX.TRMACTIVE, [1] MCTL[14]_RX.INVALDATA, [0] MCTL[14]_TX.SENTDATA, [0] MCTL[14]_RX.NEWDATA
0x9282F CAN2
  [7] MCTL[15]_TX.TRMREQ, [7] MCTL[15]_RX.TRMREQ, [6] MCTL[15]_TX.RECREQ, [6] MCTL[15]_RX.RECREQ, [4] MCTL[15]_TX.ONESHOT, [4] MCTL[15]_RX.ONESHOT, [2] MCTL[15]_TX.TRMABT, [2] MCTL[15]_RX.MSGLOST, [1] MCTL[15]_TX.TRMACTIVE, [1] MCTL[15]_RX.INVALDATA, [0] MCTL[15]_TX.SENTDATA, [0] MCTL[15]_RX.NEWDATA
0x92830 CAN2
  [7] MCTL[16]_TX.TRMREQ, [7] MCTL[16]_RX.TRMREQ, [6] MCTL[16]_TX.RECREQ, [6] MCTL[16]_RX.RECREQ, [4] MCTL[16]_TX.ONESHOT, [4] MCTL[16]_RX.ONESHOT, [2] MCTL[16]_TX.TRMABT, [2] MCTL[16]_RX.MSGLOST, [1] MCTL[16]_TX.TRMACTIVE, [1] MCTL[16]_RX.INVALDATA, [0] MCTL[16]_TX.SENTDATA, [0] MCTL[16]_RX.NEWDATA
0x92831 CAN2
  [7] MCTL[17]_TX.TRMREQ, [7] MCTL[17]_RX.TRMREQ, [6] MCTL[17]_TX.RECREQ, [6] MCTL[17]_RX.RECREQ, [4] MCTL[17]_TX.ONESHOT, [4] MCTL[17]_RX.ONESHOT, [2] MCTL[17]_TX.TRMABT, [2] MCTL[17]_RX.MSGLOST, [1] MCTL[17]_TX.TRMACTIVE, [1] MCTL[17]_RX.INVALDATA, [0] MCTL[17]_TX.SENTDATA, [0] MCTL[17]_RX.NEWDATA
0x92832 CAN2
  [7] MCTL[18]_TX.TRMREQ, [7] MCTL[18]_RX.TRMREQ, [6] MCTL[18]_TX.RECREQ, [6] MCTL[18]_RX.RECREQ, [4] MCTL[18]_TX.ONESHOT, [4] MCTL[18]_RX.ONESHOT, [2] MCTL[18]_TX.TRMABT, [2] MCTL[18]_RX.MSGLOST, [1] MCTL[18]_TX.TRMACTIVE, [1] MCTL[18]_RX.INVALDATA, [0] MCTL[18]_TX.SENTDATA, [0] MCTL[18]_RX.NEWDATA
0x92833 CAN2
  [7] MCTL[19]_TX.TRMREQ, [7] MCTL[19]_RX.TRMREQ, [6] MCTL[19]_TX.RECREQ, [6] MCTL[19]_RX.RECREQ, [4] MCTL[19]_TX.ONESHOT, [4] MCTL[19]_RX.ONESHOT, [2] MCTL[19]_TX.TRMABT, [2] MCTL[19]_RX.MSGLOST, [1] MCTL[19]_TX.TRMACTIVE, [1] MCTL[19]_RX.INVALDATA, [0] MCTL[19]_TX.SENTDATA, [0] MCTL[19]_RX.NEWDATA
0x92834 CAN2
  [7] MCTL[20]_TX.TRMREQ, [7] MCTL[20]_RX.TRMREQ, [6] MCTL[20]_TX.RECREQ, [6] MCTL[20]_RX.RECREQ, [4] MCTL[20]_TX.ONESHOT, [4] MCTL[20]_RX.ONESHOT, [2] MCTL[20]_TX.TRMABT, [2] MCTL[20]_RX.MSGLOST, [1] MCTL[20]_TX.TRMACTIVE, [1] MCTL[20]_RX.INVALDATA, [0] MCTL[20]_TX.SENTDATA, [0] MCTL[20]_RX.NEWDATA
0x92835 CAN2
  [7] MCTL[21]_TX.TRMREQ, [7] MCTL[21]_RX.TRMREQ, [6] MCTL[21]_TX.RECREQ, [6] MCTL[21]_RX.RECREQ, [4] MCTL[21]_TX.ONESHOT, [4] MCTL[21]_RX.ONESHOT, [2] MCTL[21]_TX.TRMABT, [2] MCTL[21]_RX.MSGLOST, [1] MCTL[21]_TX.TRMACTIVE, [1] MCTL[21]_RX.INVALDATA, [0] MCTL[21]_TX.SENTDATA, [0] MCTL[21]_RX.NEWDATA
0x92836 CAN2
  [7] MCTL[22]_TX.TRMREQ, [7] MCTL[22]_RX.TRMREQ, [6] MCTL[22]_TX.RECREQ, [6] MCTL[22]_RX.RECREQ, [4] MCTL[22]_TX.ONESHOT, [4] MCTL[22]_RX.ONESHOT, [2] MCTL[22]_TX.TRMABT, [2] MCTL[22]_RX.MSGLOST, [1] MCTL[22]_TX.TRMACTIVE, [1] MCTL[22]_RX.INVALDATA, [0] MCTL[22]_TX.SENTDATA, [0] MCTL[22]_RX.NEWDATA
0x92837 CAN2
  [7] MCTL[23]_TX.TRMREQ, [7] MCTL[23]_RX.TRMREQ, [6] MCTL[23]_TX.RECREQ, [6] MCTL[23]_RX.RECREQ, [4] MCTL[23]_TX.ONESHOT, [4] MCTL[23]_RX.ONESHOT, [2] MCTL[23]_TX.TRMABT, [2] MCTL[23]_RX.MSGLOST, [1] MCTL[23]_TX.TRMACTIVE, [1] MCTL[23]_RX.INVALDATA, [0] MCTL[23]_TX.SENTDATA, [0] MCTL[23]_RX.NEWDATA
0x92838 CAN2
  [7] MCTL[24]_TX.TRMREQ, [7] MCTL[24]_RX.TRMREQ, [6] MCTL[24]_TX.RECREQ, [6] MCTL[24]_RX.RECREQ, [4] MCTL[24]_TX.ONESHOT, [4] MCTL[24]_RX.ONESHOT, [2] MCTL[24]_TX.TRMABT, [2] MCTL[24]_RX.MSGLOST, [1] MCTL[24]_TX.TRMACTIVE, [1] MCTL[24]_RX.INVALDATA, [0] MCTL[24]_TX.SENTDATA, [0] MCTL[24]_RX.NEWDATA
0x92839 CAN2
  [7] MCTL[25]_TX.TRMREQ, [7] MCTL[25]_RX.TRMREQ, [6] MCTL[25]_TX.RECREQ, [6] MCTL[25]_RX.RECREQ, [4] MCTL[25]_TX.ONESHOT, [4] MCTL[25]_RX.ONESHOT, [2] MCTL[25]_TX.TRMABT, [2] MCTL[25]_RX.MSGLOST, [1] MCTL[25]_TX.TRMACTIVE, [1] MCTL[25]_RX.INVALDATA, [0] MCTL[25]_TX.SENTDATA, [0] MCTL[25]_RX.NEWDATA
0x9283A CAN2
  [7] MCTL[26]_TX.TRMREQ, [7] MCTL[26]_RX.TRMREQ, [6] MCTL[26]_TX.RECREQ, [6] MCTL[26]_RX.RECREQ, [4] MCTL[26]_TX.ONESHOT, [4] MCTL[26]_RX.ONESHOT, [2] MCTL[26]_TX.TRMABT, [2] MCTL[26]_RX.MSGLOST, [1] MCTL[26]_TX.TRMACTIVE, [1] MCTL[26]_RX.INVALDATA, [0] MCTL[26]_TX.SENTDATA, [0] MCTL[26]_RX.NEWDATA
0x9283B CAN2
  [7] MCTL[27]_TX.TRMREQ, [7] MCTL[27]_RX.TRMREQ, [6] MCTL[27]_TX.RECREQ, [6] MCTL[27]_RX.RECREQ, [4] MCTL[27]_TX.ONESHOT, [4] MCTL[27]_RX.ONESHOT, [2] MCTL[27]_TX.TRMABT, [2] MCTL[27]_RX.MSGLOST, [1] MCTL[27]_TX.TRMACTIVE, [1] MCTL[27]_RX.INVALDATA, [0] MCTL[27]_TX.SENTDATA, [0] MCTL[27]_RX.NEWDATA
0x9283C CAN2
  [7] MCTL[28]_TX.TRMREQ, [7] MCTL[28]_RX.TRMREQ, [6] MCTL[28]_TX.RECREQ, [6] MCTL[28]_RX.RECREQ, [4] MCTL[28]_TX.ONESHOT, [4] MCTL[28]_RX.ONESHOT, [2] MCTL[28]_TX.TRMABT, [2] MCTL[28]_RX.MSGLOST, [1] MCTL[28]_TX.TRMACTIVE, [1] MCTL[28]_RX.INVALDATA, [0] MCTL[28]_TX.SENTDATA, [0] MCTL[28]_RX.NEWDATA
0x9283D CAN2
  [7] MCTL[29]_TX.TRMREQ, [7] MCTL[29]_RX.TRMREQ, [6] MCTL[29]_TX.RECREQ, [6] MCTL[29]_RX.RECREQ, [4] MCTL[29]_TX.ONESHOT, [4] MCTL[29]_RX.ONESHOT, [2] MCTL[29]_TX.TRMABT, [2] MCTL[29]_RX.MSGLOST, [1] MCTL[29]_TX.TRMACTIVE, [1] MCTL[29]_RX.INVALDATA, [0] MCTL[29]_TX.SENTDATA, [0] MCTL[29]_RX.NEWDATA
0x9283E CAN2
  [7] MCTL[30]_TX.TRMREQ, [7] MCTL[30]_RX.TRMREQ, [6] MCTL[30]_TX.RECREQ, [6] MCTL[30]_RX.RECREQ, [4] MCTL[30]_TX.ONESHOT, [4] MCTL[30]_RX.ONESHOT, [2] MCTL[30]_TX.TRMABT, [2] MCTL[30]_RX.MSGLOST, [1] MCTL[30]_TX.TRMACTIVE, [1] MCTL[30]_RX.INVALDATA, [0] MCTL[30]_TX.SENTDATA, [0] MCTL[30]_RX.NEWDATA
0x9283F CAN2
  [7] MCTL[31]_TX.TRMREQ, [7] MCTL[31]_RX.TRMREQ, [6] MCTL[31]_TX.RECREQ, [6] MCTL[31]_RX.RECREQ, [4] MCTL[31]_TX.ONESHOT, [4] MCTL[31]_RX.ONESHOT, [2] MCTL[31]_TX.TRMABT, [2] MCTL[31]_RX.MSGLOST, [1] MCTL[31]_TX.TRMACTIVE, [1] MCTL[31]_RX.INVALDATA, [0] MCTL[31]_TX.SENTDATA, [0] MCTL[31]_RX.NEWDATA
0xA0000 USB0 16-bit
  [10] SYSCFG.SCKE, [4] SYSCFG.DPRPU, [0] SYSCFG.USBE
0xA0004 USB0 16-bit
  [1:0] SYSSTS0.LNST
0xA0008 USB0 16-bit
  [8] DVSTCTR0.WKUP, [2:0] DVSTCTR0.RHST
0xA0020 USB0 16-bit
  [15] CFIFOSEL.RCNT, [14] CFIFOSEL.REW, [10] CFIFOSEL.MBW, [8] CFIFOSEL.BIGEND, [5] CFIFOSEL.ISEL, [3:0] CFIFOSEL.CURPIPE
0xA0022 USB0 16-bit
  [15] CFIFOCTR.BVAL, [14] CFIFOCTR.BCLR, [13] CFIFOCTR.FRDY, [8:0] CFIFOCTR.DTLN
0xA0028 USB0 16-bit
  [15] D0FIFOSEL.RCNT, [14] D0FIFOSEL.REW, [13] D0FIFOSEL.DCLRM, [12] D0FIFOSEL.DREQE, [10] D0FIFOSEL.MBW, [8] D0FIFOSEL.BIGEND, [3:0] D0FIFOSEL.CURPIPE
0xA002A USB0 16-bit
  [15] D0FIFOCTR.BVAL, [14] D0FIFOCTR.BCLR, [13] D0FIFOCTR.FRDY, [8:0] D0FIFOCTR.DTLN
0xA002C USB0 16-bit
  [15] D1FIFOSEL.RCNT, [14] D1FIFOSEL.REW, [13] D1FIFOSEL.DCLRM, [12] D1FIFOSEL.DREQE, [10] D1FIFOSEL.MBW, [8] D1FIFOSEL.BIGEND, [3:0] D1FIFOSEL.CURPIPE
0xA002E USB0 16-bit
  [15] D1FIFOCTR.BVAL, [14] D1FIFOCTR.BCLR, [13] D1FIFOCTR.FRDY, [8:0] D1FIFOCTR.DTLN
0xA0030 USB0 16-bit
  [15] INTENB0.VBSE, [14] INTENB0.RSME, [13] INTENB0.SOFE, [12] INTENB0.DVSE, [11] INTENB0.CTRE, [10] INTENB0.BEMPE, [9] INTENB0.NRDYE, [8] INTENB0.BRDYE
0xA0036 USB0 16-bit
  [n] BRDYENB.PIPE{n}BRDYE (n=0..9)
0xA0038 USB0 16-bit
  [n] NRDYENB.PIPE{n}NRDYE (n=0..9)
0xA003A USB0 16-bit
  [n] BEMPENB.PIPE{n}BEMPE (n=0..9)
0xA003C USB0 16-bit
  [6] SOFCFG.BRDYM, [4] SOFCFG.EDGESTS
0xA0040 USB0 16-bit
  [15] INTSTS0.VBINT, [14] INTSTS0.RESM, [13] INTSTS0.SOFR, [12] INTSTS0.DVST, [11] INTSTS0.CTRT, [10] INTSTS0.BEMP, [9] INTSTS0.NRDY, [8] INTSTS0.BRDY, [7] INTSTS0.VBSTS, [6:4] INTSTS0.DVSQ, [3] INTSTS0.VALID, [2:0] INTSTS0.CTSQ
0xA0046 USB0 16-bit
  [n] BRDYSTS.PIPE{n}BRDY (n=0..9)
0xA0048 USB0 16-bit
  [n] NRDYSTS.PIPE{n}NRDYE (n=0..9)
0xA004A USB0 16-bit
  [9] BEMPSTS.PIPE9BEMPE, [8] BEMPSTS.PIPE8BEMPE, [n] BEMPSTS.PIPE{n}BENP (n=0..7)
0xA004C USB0 16-bit
  [15] FRMNUM.OVRN, [14] FRMNUM.CRCE, [10:0] FRMNUM.FRNM
0xA004E USB0 16-bit
  [15] DVCHGR.DVCHG
0xA0050 USB0 16-bit
  [11:8] USBADDR.STSRECOV, [6:0] USBADDR.USBADDR
0xA0054 USB0 16-bit
  [15:8] USBREQ.BREQUEST, [7:0] USBREQ.BMREQUESTTYPE
0xA005C USB0 16-bit
  [7] DCPCFG.SHTNAK
0xA005E USB0 16-bit
  [6:0] DCPMAXP.MXPS
0xA0060 USB0 16-bit
  [15] DCPCTR.BSTS, [8] DCPCTR.SQCLR, [7] DCPCTR.SQSET, [6] DCPCTR.SQMON, [5] DCPCTR.PBUSY, [2] DCPCTR.CCPL, [1:0] DCPCTR.PID
0xA0064 USB0 16-bit
  [3:0] PIPESEL.PIPESEL
0xA0068 USB0 16-bit
  [15:14] PIPECFG.TYPE, [10] PIPECFG.BFRE, [9] PIPECFG.DBLB, [7] PIPECFG.SHTNAK, [4] PIPECFG.DIR, [3:0] PIPECFG.EPNUM
0xA006C USB0 16-bit
  [8:0] PIPEMAXP.MXPS
0xA006E USB0 16-bit
  [12] PIPEPERI.IFIS, [2:0] PIPEPERI.IITV
0xA0070 USB0 16-bit
  [15] PIPE1CTR.BSTS, [14] PIPE1CTR.INBUFM, [10] PIPE1CTR.ATREPM, [9] PIPE1CTR.ACLRM, [8] PIPE1CTR.SQCLR, [7] PIPE1CTR.SQSET, [6] PIPE1CTR.SQMON, [5] PIPE1CTR.PBUSY, [1:0] PIPE1CTR.PID
0xA0072 USB0 16-bit
  [15] PIPE2CTR.BSTS, [14] PIPE2CTR.INBUFM, [10] PIPE2CTR.ATREPM, [9] PIPE2CTR.ACLRM, [8] PIPE2CTR.SQCLR, [7] PIPE2CTR.SQSET, [6] PIPE2CTR.SQMON, [5] PIPE2CTR.PBUSY, [1:0] PIPE2CTR.PID
0xA0074 USB0 16-bit
  [15] PIPE3CTR.BSTS, [14] PIPE3CTR.INBUFM, [10] PIPE3CTR.ATREPM, [9] PIPE3CTR.ACLRM, [8] PIPE3CTR.SQCLR, [7] PIPE3CTR.SQSET, [6] PIPE3CTR.SQMON, [5] PIPE3CTR.PBUSY, [1:0] PIPE3CTR.PID
0xA0076 USB0 16-bit
  [15] PIPE4CTR.BSTS, [14] PIPE4CTR.INBUFM, [10] PIPE4CTR.ATREPM, [9] PIPE4CTR.ACLRM, [8] PIPE4CTR.SQCLR, [7] PIPE4CTR.SQSET, [6] PIPE4CTR.SQMON, [5] PIPE4CTR.PBUSY, [1:0] PIPE4CTR.PID
0xA0078 USB0 16-bit
  [15] PIPE5CTR.BSTS, [14] PIPE5CTR.INBUFM, [10] PIPE5CTR.ATREPM, [9] PIPE5CTR.ACLRM, [8] PIPE5CTR.SQCLR, [7] PIPE5CTR.SQSET, [6] PIPE5CTR.SQMON, [5] PIPE5CTR.PBUSY, [1:0] PIPE5CTR.PID
0xA007A USB0 16-bit
  [15] PIPE6CTR.BSTS, [9] PIPE6CTR.ACLRM, [8] PIPE6CTR.SQCLR, [7] PIPE6CTR.SQSET, [6] PIPE6CTR.SQMON, [5] PIPE6CTR.PBUSY, [1:0] PIPE6CTR.PID
0xA007C USB0 16-bit
  [15] PIPE7CTR.BSTS, [9] PIPE7CTR.ACLRM, [8] PIPE7CTR.SQCLR, [7] PIPE7CTR.SQSET, [6] PIPE7CTR.SQMON, [5] PIPE7CTR.PBUSY, [1:0] PIPE7CTR.PID
0xA007E USB0 16-bit
  [15] PIPE8CTR.BSTS, [9] PIPE8CTR.ACLRM, [8] PIPE8CTR.SQCLR, [7] PIPE8CTR.SQSET, [6] PIPE8CTR.SQMON, [5] PIPE8CTR.PBUSY, [1:0] PIPE8CTR.PID
0xA0080 USB0 16-bit
  [15] PIPE9CTR.BSTS, [9] PIPE9CTR.ACLRM, [8] PIPE9CTR.SQCLR, [7] PIPE9CTR.SQSET, [6] PIPE9CTR.SQMON, [5] PIPE9CTR.PBUSY, [1:0] PIPE9CTR.PID
0xA0090 USB0 16-bit
  [9] PIPE1TRE.TRENB, [8] PIPE1TRE.TRCLR
0xA0094 USB0 16-bit
  [9] PIPE2TRE.TRENB, [8] PIPE2TRE.TRCLR
0xA0098 USB0 16-bit
  [9] PIPE3TRE.TRENB, [8] PIPE3TRE.TRCLR
0xA009C USB0 16-bit
  [9] PIPE4TRE.TRENB, [8] PIPE4TRE.TRCLR
0xA00A0 USB0 16-bit
  [9] PIPE5TRE.TRENB, [8] PIPE5TRE.TRCLR
0xA0400 USB 32-bit
  [23] DPUSR0R.DVBSTS0, [17] DPUSR0R.DM0, [16] DPUSR0R.DP0, [4] DPUSR0R.FIXPHY0, [0] DPUSR0R.SRPC0
0xA0404 USB 32-bit
  [23] DPUSR1R.DVBINT0, [16] DPUSR1R.DPINT0, [7] DPUSR1R.DVBSE0, [0] DPUSR1R.DPINTE0
0x7FC402 FLASH
  [4] FMODR.FRDMD
0x7FC410 FLASH
  [7] FASTAT.ROMAE, [4] FASTAT.CMDLK, [3] FASTAT.DFLAE, [1] FASTAT.DFLRPE, [0] FASTAT.DFLWPE
0x7FC411 FLASH
  [7] FAEINT.ROMAEIE, [4] FAEINT.CMDLKIE, [3] FAEINT.DFLAEIE, [1] FAEINT.DFLRPEIE, [0] FAEINT.DFLWPEIE
0x7FC412 FLASH
  [0] FRDYIE.FRDYIE
0x7FC440 FLASH 16-bit
  [15:8] DFLRE0.KEY, [n] DFLRE0.DBRE{n:02} (n=0..7)
0x7FC442 FLASH 16-bit
  [15:8] DFLRE1.KEY, [n-8] DFLRE1.DBRE{n:02} (n=8..15)
0x7FC450 FLASH 16-bit
  [15:8] DFLWE0.KEY, [7] DFLWE0.DBWE07, [6] DFLWE0.DBW006, [n] DFLWE0.DBWE{n:02} (n=0..5)
0x7FC452 FLASH 16-bit
  [15:8] DFLWE1.KEY, [n-8] DFLWE1.DBWE{n:02} (n=8..15)
0x7FC454 FLASH 16-bit
  [15:8] FCURAME.KEY, [0] FCURAME.FCRME
0x7FFFB0 FLASH
  [7] FSTATR0.FRDY, [6] FSTATR0.ILGLERR, [5] FSTATR0.ERSERR, [4] FSTATR0.PRGERR, [3] FSTATR0.SUSRDY, [1] FSTATR0.ERSSPD, [0] FSTATR0.PRGSPD
0x7FFFB1 FLASH
  [7] FSTATR1.FCUERR, [4] FSTATR1.FLOCKST
0x7FFFB2 FLASH 16-bit
  [15:8] FENTRYR.FEKEY, [7] FENTRYR.FENTRYD, [n] FENTRYR.FENTRY{n} (n=0..3)
0x7FFFB4 FLASH 16-bit
  [15:8] FPROTR.FPKEY, [0] FPROTR.FPROTCN
0x7FFFB6 FLASH 16-bit
  [15:8] FRESETR.FRKEY, [0] FRESETR.FRESET
0x7FFFBA FLASH 16-bit
  [15:8] FCMDR.CMDR, [7:0] FCMDR.PCMDR
0x7FFFC8 FLASH 16-bit
  [0] FCPSR.ESUSPMD
0x7FFFCA FLASH 16-bit
  [15] DFLBCCNT.BCSIZE, [10:0] DFLBCCNT.BCADR
0x7FFFCC FLASH 16-bit
  [7:0] FPESTAT.PEERRST
0x7FFFCE FLASH 16-bit
  [0] DFLBCSTAT.BCST
0x7FFFE8 FLASH 16-bit
  [7:0] PCKAR.PCKA
